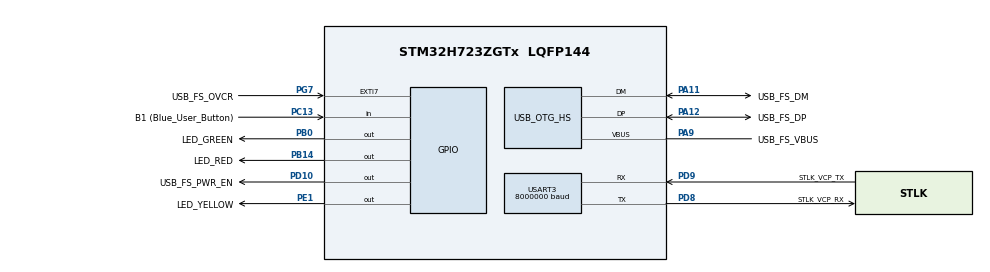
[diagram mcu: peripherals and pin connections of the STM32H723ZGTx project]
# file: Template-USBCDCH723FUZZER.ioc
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CORTEX_M7.CPU_DCache=Disabled
CORTEX_M7.CPU_ICache=Disabled
CRC.InputDataFormat=CRC_INPUTDATA_FORMAT_WORDS
CRC.InputDataInversionMode=CRC_INPUTDATA_INVERSION_WORD
CRC.OutputDataInversionMode=CRC_OUTPUTDATA_INVERSION_ENABLE
Mcu.Family=STM32H7
Mcu.Name=STM32H723ZGTx
Mcu.Package=LQFP144
NVIC.OTG_HS_IRQn=true\:5\:0\:true\:false\:true\:false\:true\:true
NVIC.PriorityGroup=NVIC_PRIORITYGROUP_4
NVIC.TIM16_IRQn=true\:15\:0\:false\:false\:true\:false\:true\:true
NVIC.TimeBase=TIM16_IRQn
NVIC.TimeBaseIP=TIM16
PA1.GPIO_Label=RMII_REF_CLK
PA1.Signal=ETH_REF_CLK
PA10.GPIO_Label=USB_FS_ID
PA10.Signal=USB_OTG_HS_ID
PA11.GPIO_Label=USB_FS_DM
PA11.Mode=Device_Only_FS
PA11.Signal=USB_OTG_HS_DM
PA12.GPIO_Label=USB_FS_DP
PA12.Mode=Device_Only_FS
PA12.Signal=USB_OTG_HS_DP
PA13(JTMS/SWDIO).GPIO_Label=SWDIO
PA13(JTMS/SWDIO).Mode=Trace_Asynchronous_SW
PA13(JTMS/SWDIO).Signal=DEBUG_JTMS-SWDIO
PA14(JTCK/SWCLK).GPIO_Label=SWCLK
PA14(JTCK/SWCLK).Mode=Trace_Asynchronous_SW
PA14(JTCK/SWCLK).Signal=DEBUG_JTCK-SWCLK
PA2.GPIO_Label=RMII_MDIO
PA2.Signal=ETH_MDIO
PA7.GPIO_Label=RMII_CRS_DV
PA7.Signal=ETH_CRS_DV
PA9.GPIO_Label=USB_FS_VBUS
PA9.Mode=Activate_VBUS_FS
PA9.Signal=USB_OTG_HS_VBUS
PB0.GPIO_Label=LED_GREEN
PB0.Signal=GPIO_Output
PB13.GPIO_Label=RMII_TXD1
PB13.Signal=ETH_TXD1
PB14.GPIO_Label=LED_RED
PB14.Signal=GPIO_Output
PB3(JTDO/TRACESWO).GPIO_Label=SWO
PB3(JTDO/TRACESWO).Mode=Trace_Asynchronous_SW
PB3(JTDO/TRACESWO).Signal=DEBUG_JTDO-SWO
PC1.GPIO_Label=RMII_MDC
PC1.Signal=ETH_MDC
PC13.GPIO_Label=B1 (Blue_User_Button)
PC13.Signal=GPIO_Input
PC14-OSC32_IN.Mode=LSE-External-Oscillator
PC14-OSC32_IN.Signal=RCC_OSC32_IN
PC15-OSC32_OUT.Mode=LSE-External-Oscillator
PC15-OSC32_OUT.Signal=RCC_OSC32_OUT
PC4.GPIO_Label=RMII_RXD0
PC4.Signal=ETH_RXD0
PC5.GPIO_Label=RMII_RXD1
PC5.Signal=ETH_RXD1
PD10.GPIO_Label=USB_FS_PWR_EN
PD10.Signal=GPIO_Output
PD8.GPIO_Label=STLK_VCP_RX
PD8.Mode=Asynchronous
PD8.Signal=USART3_TX
PD9.GPIO_Label=STLK_VCP_TX
PD9.Mode=Asynchronous
PD9.Signal=USART3_RX
PE1.GPIO_Label=LED_YELLOW
PE1.Signal=GPIO_Output
PG11.GPIO_Label=RMII_TX_EN
PG11.Signal=ETH_TX_EN
PG13.GPIO_Label=RMII_TXD0
PG13.Signal=ETH_TXD0
PG7.GPIO_Label=USB_FS_OVCR
PG7.Signal=GPXTI7
PH0-OSC_IN.GPIO_Label=MCO
PH0-OSC_IN.Mode=HSE-External-Clock-Source
PH0-OSC_IN.Signal=RCC_OSC_IN
PH1-OSC_OUT.Signal=RCC_OSC_OUT
ProjectManager.HeapSize=0x200
ProjectManager.StackSize=0x400
ProjectManager.TargetToolchain=STM32CubeIDE
RCC.ADCFreq_Value=76000000
RCC.APB1Freq_Value=137500000
RCC.APB2Freq_Value=137500000
RCC.APB3Freq_Value=137500000
RCC.APB4Freq_Value=137500000
RCC.CortexFreq_Value=550000000
RCC.D1PPRE=RCC_APB3_DIV2
RCC.D2PPRE1=RCC_APB1_DIV2
RCC.D2PPRE2=RCC_APB2_DIV2
RCC.D3PPRE=RCC_APB4_DIV2
RCC.DIVM1=4
RCC.DIVM2=1
RCC.DIVN1=275
RCC.DIVN2=19
RCC.DIVP1=1
RCC.DIVQ1=4
RCC.HCLKFreq_Value=275000000
RCC.HPRE=RCC_HCLK_DIV2
RCC.HSE_VALUE=8000000
RCC.PLLFRACN=0
RCC.PLLSourceVirtual=RCC_PLLSOURCE_HSE
RCC.SYSCLKFreq_VALUE=550000000
RCC.SYSCLKSource=RCC_SYSCLKSOURCE_PLLCLK
RCC.USBCLockSelection=RCC_USBCLKSOURCE_HSI48
RCC.USBFreq_Value=48000000
USART3.BaudRate=8000000
USART3.VirtualMode-Asynchronous=VM_ASYNC
USB_DEVICE.CLASS_NAME_HS=CDC
USB_DEVICE.VirtualMode=Cdc
USB_DEVICE.VirtualModeHS=Cdc_HS
USB_OTG_HS.VirtualMode-Device_Only_FS=Device_Only_FS
VP_CRC_VS_CRC.Mode=CRC_Activate
VP_RNG_VS_RNG.Mode=RNG_Activate
VP_SYS_VS_tim16.Mode=TIM16
VP_USB_DEVICE_VS_USB_DEVICE_CDC_HS.Mode=CDC_HS
board=NUCLEO-H723ZG

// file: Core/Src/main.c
/* USER CODE BEGIN Header */
/**
  ******************************************************************************
  * @file           : main.c
  * @brief          : Main program body
  ******************************************************************************
  * @attention
  *
  * Copyright (c) 2023 STMicroelectronics.
  * All rights reserved.
  *
  * This software is licensed under terms that can be found in the LICENSE file
  * in the root directory of this software component.
  * If no LICENSE file comes with this software, it is provided AS-IS.
  *
  ******************************************************************************
  */
/* USER CODE END Header */
#include "main.h"
#include "usb_device.h"

/* USER CODE BEGIN Includes */
#include "fuzzing.h"
#include "app_main.h"
/* USER CODE END Includes */

CRC_HandleTypeDef hcrc;

RNG_HandleTypeDef hrng;

UART_HandleTypeDef huart3;

void SystemClock_Config(void);
static void MX_GPIO_Init(void);
static void MX_USART3_UART_Init(void);
static void MX_CRC_Init(void);
static void MX_RNG_Init(void);
/* USER CODE BEGIN PFP */
void __io_putchar(uint8_t ch) {
HAL_UART_Transmit(&huart3, &ch, 1, 1);
}
/* USER CODE END PFP */

int main(void)
{
  /* USER CODE BEGIN 1 */
	SCB_EnableICache();  // we will only use the instruction cache
	//SCB_DisableDCache();
  /* USER CODE END 1 */

  /* MCU Configuration--------------------------------------------------------*/

  /* Reset of all peripherals, Initializes the Flash interface and the Systick. */
  HAL_Init();

  /* Configure the system clock */
  SystemClock_Config();

  /* Initialize all configured peripherals */
  MX_GPIO_Init();
  MX_USART3_UART_Init();
  MX_USB_DEVICE_Init();
  MX_CRC_Init();
  MX_RNG_Init();
  /* USER CODE BEGIN 2 */

  uint8_t test1[] = "test1\n";

   HAL_UART_Transmit(&huart3, test1, 6, 100);
   printf("Hola\n");

  activateCortexMtrapsUNA();
  app_main();

  /* USER CODE END 2 */

  /* Infinite loop */
  while (1)
  {

  }
}

void SystemClock_Config(void)
{
  RCC_OscInitTypeDef RCC_OscInitStruct = {0};
  RCC_ClkInitTypeDef RCC_ClkInitStruct = {0};

  /** Supply configuration update enable
  */
  HAL_PWREx_ConfigSupply(PWR_LDO_SUPPLY);

  /** Configure the main internal regulator output voltage
  */
  __HAL_PWR_VOLTAGESCALING_CONFIG(PWR_REGULATOR_VOLTAGE_SCALE0);

  while(!__HAL_PWR_GET_FLAG(PWR_FLAG_VOSRDY)) {}

  /** Initializes the RCC Oscillators according to the specified parameters
  * in the RCC_OscInitTypeDef structure.
  */
  RCC_OscInitStruct.OscillatorType = RCC_OSCILLATORTYPE_HSI48|RCC_OSCILLATORTYPE_HSE;
  RCC_OscInitStruct.HSEState = RCC_HSE_BYPASS;
  RCC_OscInitStruct.HSI48State = RCC_HSI48_ON;
  RCC_OscInitStruct.PLL.PLLState = RCC_PLL_ON;
  RCC_OscInitStruct.PLL.PLLSource = RCC_PLLSOURCE_HSE;
  RCC_OscInitStruct.PLL.PLLM = 4;
  RCC_OscInitStruct.PLL.PLLN = 275;
  RCC_OscInitStruct.PLL.PLLP = 1;
  RCC_OscInitStruct.PLL.PLLQ = 4;
  RCC_OscInitStruct.PLL.PLLR = 2;
  RCC_OscInitStruct.PLL.PLLRGE = RCC_PLL1VCIRANGE_1;
  RCC_OscInitStruct.PLL.PLLVCOSEL = RCC_PLL1VCOWIDE;
  RCC_OscInitStruct.PLL.PLLFRACN = 0;
  if (HAL_RCC_OscConfig(&RCC_OscInitStruct) != HAL_OK)
  {
    Error_Handler();
  }

  /** Initializes the CPU, AHB and APB buses clocks
  */
  RCC_ClkInitStruct.ClockType = RCC_CLOCKTYPE_HCLK|RCC_CLOCKTYPE_SYSCLK
                              |RCC_CLOCKTYPE_PCLK1|RCC_CLOCKTYPE_PCLK2
                              |RCC_CLOCKTYPE_D3PCLK1|RCC_CLOCKTYPE_D1PCLK1;
  RCC_ClkInitStruct.SYSCLKSource = RCC_SYSCLKSOURCE_PLLCLK;
  RCC_ClkInitStruct.SYSCLKDivider = RCC_SYSCLK_DIV1;
  RCC_ClkInitStruct.AHBCLKDivider = RCC_HCLK_DIV2;
  RCC_ClkInitStruct.APB3CLKDivider = RCC_APB3_DIV2;
  RCC_ClkInitStruct.APB1CLKDivider = RCC_APB1_DIV2;
  RCC_ClkInitStruct.APB2CLKDivider = RCC_APB2_DIV2;
  RCC_ClkInitStruct.APB4CLKDivider = RCC_APB4_DIV2;

  if (HAL_RCC_ClockConfig(&RCC_ClkInitStruct, FLASH_LATENCY_3) != HAL_OK)
  {
    Error_Handler();
  }
}

static void MX_CRC_Init(void)
{

  hcrc.Instance = CRC;
  hcrc.Init.DefaultPolynomialUse = DEFAULT_POLYNOMIAL_ENABLE;
  hcrc.Init.DefaultInitValueUse = DEFAULT_INIT_VALUE_ENABLE;
  hcrc.Init.InputDataInversionMode = CRC_INPUTDATA_INVERSION_WORD;
  hcrc.Init.OutputDataInversionMode = CRC_OUTPUTDATA_INVERSION_ENABLE;
  hcrc.InputDataFormat = CRC_INPUTDATA_FORMAT_WORDS;
  if (HAL_CRC_Init(&hcrc) != HAL_OK)
  {
    Error_Handler();
  }

}

static void MX_RNG_Init(void)
{

  hrng.Instance = RNG;
  hrng.Init.ClockErrorDetection = RNG_CED_ENABLE;
  if (HAL_RNG_Init(&hrng) != HAL_OK)
  {
    Error_Handler();
  }

}

static void MX_USART3_UART_Init(void)
{

  huart3.Instance = USART3;
  huart3.Init.BaudRate = 8000000;
  huart3.Init.WordLength = UART_WORDLENGTH_8B;
  huart3.Init.StopBits = UART_STOPBITS_1;
  huart3.Init.Parity = UART_PARITY_NONE;
  huart3.Init.Mode = UART_MODE_TX_RX;
  huart3.Init.HwFlowCtl = UART_HWCONTROL_NONE;
  huart3.Init.OverSampling = UART_OVERSAMPLING_16;
  huart3.Init.OneBitSampling = UART_ONE_BIT_SAMPLE_DISABLE;
  huart3.Init.ClockPrescaler = UART_PRESCALER_DIV1;
  huart3.AdvancedInit.AdvFeatureInit = UART_ADVFEATURE_NO_INIT;
  if (HAL_UART_Init(&huart3) != HAL_OK)
  {
    Error_Handler();
  }
  if (HAL_UARTEx_SetTxFifoThreshold(&huart3, UART_TXFIFO_THRESHOLD_1_8) != HAL_OK)
  {
    Error_Handler();
  }
  if (HAL_UARTEx_SetRxFifoThreshold(&huart3, UART_RXFIFO_THRESHOLD_1_8) != HAL_OK)
  {
    Error_Handler();
  }
  if (HAL_UARTEx_DisableFifoMode(&huart3) != HAL_OK)
  {
    Error_Handler();
  }

}

static void MX_GPIO_Init(void)
{
  GPIO_InitTypeDef GPIO_InitStruct = {0};

  /* GPIO Ports Clock Enable */
  __HAL_RCC_GPIOC_CLK_ENABLE();
  __HAL_RCC_GPIOH_CLK_ENABLE();
  __HAL_RCC_GPIOA_CLK_ENABLE();
  __HAL_RCC_GPIOB_CLK_ENABLE();
  __HAL_RCC_GPIOD_CLK_ENABLE();
  __HAL_RCC_GPIOG_CLK_ENABLE();
  __HAL_RCC_GPIOE_CLK_ENABLE();

  /*Configure GPIO pin Output Level */
  HAL_GPIO_WritePin(GPIOB, LED_GREEN_Pin|LED_RED_Pin, GPIO_PIN_RESET);

  /*Configure GPIO pin Output Level */
  HAL_GPIO_WritePin(USB_FS_PWR_EN_GPIO_Port, USB_FS_PWR_EN_Pin, GPIO_PIN_RESET);

  /*Configure GPIO pin Output Level */
  HAL_GPIO_WritePin(LED_YELLOW_GPIO_Port, LED_YELLOW_Pin, GPIO_PIN_RESET);

  /*Configure GPIO pin : B1_Pin */
  GPIO_InitStruct.Pin = B1_Pin;
  GPIO_InitStruct.Mode = GPIO_MODE_INPUT;
  GPIO_InitStruct.Pull = GPIO_NOPULL;
  HAL_GPIO_Init(B1_GPIO_Port, &GPIO_InitStruct);

  /*Configure GPIO pins : RMII_MDC_Pin RMII_RXD0_Pin RMII_RXD1_Pin */
  GPIO_InitStruct.Pin = RMII_MDC_Pin|RMII_RXD0_Pin|RMII_RXD1_Pin;
  GPIO_InitStruct.Mode = GPIO_MODE_AF_PP;
  GPIO_InitStruct.Pull = GPIO_NOPULL;
  GPIO_InitStruct.Speed = GPIO_SPEED_FREQ_LOW;
  GPIO_InitStruct.Alternate = GPIO_AF11_ETH;
  HAL_GPIO_Init(GPIOC, &GPIO_InitStruct);

  /*Configure GPIO pins : RMII_REF_CLK_Pin RMII_MDIO_Pin RMII_CRS_DV_Pin */
  GPIO_InitStruct.Pin = RMII_REF_CLK_Pin|RMII_MDIO_Pin|RMII_CRS_DV_Pin;
  GPIO_InitStruct.Mode = GPIO_MODE_AF_PP;
  GPIO_InitStruct.Pull = GPIO_NOPULL;
  GPIO_InitStruct.Speed = GPIO_SPEED_FREQ_LOW;
  GPIO_InitStruct.Alternate = GPIO_AF11_ETH;
  HAL_GPIO_Init(GPIOA, &GPIO_InitStruct);

  /*Configure GPIO pins : LED_GREEN_Pin LED_RED_Pin */
  GPIO_InitStruct.Pin = LED_GREEN_Pin|LED_RED_Pin;
  GPIO_InitStruct.Mode = GPIO_MODE_OUTPUT_PP;
  GPIO_InitStruct.Pull = GPIO_NOPULL;
  GPIO_InitStruct.Speed = GPIO_SPEED_FREQ_LOW;
  HAL_GPIO_Init(GPIOB, &GPIO_InitStruct);

  /*Configure GPIO pin : RMII_TXD1_Pin */
  GPIO_InitStruct.Pin = RMII_TXD1_Pin;
  GPIO_InitStruct.Mode = GPIO_MODE_AF_PP;
  GPIO_InitStruct.Pull = GPIO_NOPULL;
  GPIO_InitStruct.Speed = GPIO_SPEED_FREQ_LOW;
  GPIO_InitStruct.Alternate = GPIO_AF11_ETH;
  HAL_GPIO_Init(RMII_TXD1_GPIO_Port, &GPIO_InitStruct);

  /*Configure GPIO pin : USB_FS_PWR_EN_Pin */
  GPIO_InitStruct.Pin = USB_FS_PWR_EN_Pin;
  GPIO_InitStruct.Mode = GPIO_MODE_OUTPUT_PP;
  GPIO_InitStruct.Pull = GPIO_NOPULL;
  GPIO_InitStruct.Speed = GPIO_SPEED_FREQ_LOW;
  HAL_GPIO_Init(USB_FS_PWR_EN_GPIO_Port, &GPIO_InitStruct);

  /*Configure GPIO pin : USB_FS_OVCR_Pin */
  GPIO_InitStruct.Pin = USB_FS_OVCR_Pin;
  GPIO_InitStruct.Mode = GPIO_MODE_IT_RISING;
  GPIO_InitStruct.Pull = GPIO_NOPULL;
  HAL_GPIO_Init(USB_FS_OVCR_GPIO_Port, &GPIO_InitStruct);

  /*Configure GPIO pins : RMII_TX_EN_Pin RMII_TXD0_Pin */
  GPIO_InitStruct.Pin = RMII_TX_EN_Pin|RMII_TXD0_Pin;
  GPIO_InitStruct.Mode = GPIO_MODE_AF_PP;
  GPIO_InitStruct.Pull = GPIO_NOPULL;
  GPIO_InitStruct.Speed = GPIO_SPEED_FREQ_LOW;
  GPIO_InitStruct.Alternate = GPIO_AF11_ETH;
  HAL_GPIO_Init(GPIOG, &GPIO_InitStruct);

  /*Configure GPIO pin : LED_YELLOW_Pin */
  GPIO_InitStruct.Pin = LED_YELLOW_Pin;
  GPIO_InitStruct.Mode = GPIO_MODE_OUTPUT_PP;
  GPIO_InitStruct.Pull = GPIO_NOPULL;
  GPIO_InitStruct.Speed = GPIO_SPEED_FREQ_LOW;
  HAL_GPIO_Init(LED_YELLOW_GPIO_Port, &GPIO_InitStruct);

}

void HAL_TIM_PeriodElapsedCallback(TIM_HandleTypeDef *htim)
{
  if (htim->Instance == TIM16) {
    HAL_IncTick();
  }
}

void Error_Handler(void)
{
  __disable_irq();
  while (1)
  {
  }
}
